# nrf9220_application register map
Vendor: Nordic Semiconductor; Series: nRF92; File version: 1
CPU: CM33 r0p4, little endian, MPU, FPU, 3 interrupt priority bits, 480 interrupts, 4 SAU regions
Registers are 32-bit, read-write, reset 0x0 unless marked. A register's access mark holds for its fields unless they carry their own. Offsets are from the block's base; [hi:lo] are bit positions; lines under a group give offsets from that group; {n}, {i} and the like mark numbered series.

## GLOBAL_MICR_NS — MICR
Base 0x0FFF6000
0x80 SIPINFO group — SIP-specific device info
  0x00 PARTNO ro reset 0xFFFFFFFF — SIP part number
  {0x4+j} HWREVISION[{j}] (j=0..3) 8-bit ro reset 0xFF — Description collection: SIP hardware revision, encoded in ASCII, ex B0A or B1A
    [7:0] HWREVISION
  {0x8+j} VARIANT[{j}] (j=0..3) 8-bit ro reset 0xFF — Description collection: SIP VARIANT, encoded in ASCII, ex SIAA, SIBA or SICA
    [7:0] VARIANT
  {0x10+j} TESTSITE[{j}] (j=0..3) 8-bit ro — Description collection: Test site, in ascii
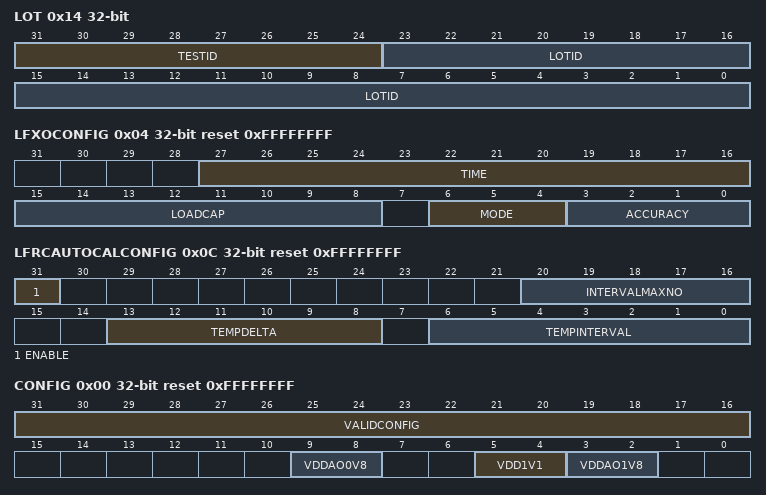
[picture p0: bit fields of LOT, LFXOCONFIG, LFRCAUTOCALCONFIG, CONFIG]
  0x14 LOT ro — Lot number + test index in hex format (number digits 0-9).
    [31:24] TESTID — Test ID in hex format
    [23:0] LOTID — Lot number in hex format
  {0x18+j} TESTPROGRAMID[{j}] (j=0..3) 8-bit ro — Description collection: Test program id, in ascii
  0x1C OSATPARTNO ro reset 0xFFFFFFFF — OSAT part number
  {0x20+j} HWBUILDVERSION[{j}] (j=0..3) 8-bit ro reset 0xFF — Description collection: OSAT production build version
  0x24 OVERRIDE group — Unspecified
    0x00 LFOSC group — Unspecified
      0x00 CONFIG reset 0xFFFFFFFF — LF oscillator configuration. Note. This configuration overrides corresponding LF oscillator configuration in BICR when set.
        [3:0] SRC — LF oscillator source.
          15=Unconfigured (LF oscillator source is unconfigured. Default will be used.); 0=LFXO (Use LFXO as source for the LF oscillator.); 1=LFRC (Use LFRC as source for the LF oscillator.); 2=LFLPRC (Use LFLPRC as source for the LF oscillator.); 3=Synth (Use LF Synth as source for the LF oscillator.)
      0x04 LFXOCONFIG reset 0xFFFFFFFF — LFXO configuration. Note. This configuration overrides corresponding LFXO configuration in BICR when set.
        [27:16] TIME — LFXO startup time in ms.
          0xFFF=Unconfigured (Startup time has not been configured.)
        [15:8] LOADCAP — Built-in load capacitors selection in 1 pF steps. Max. value 25 pF.
          255=Unconfigured (The built-in load capacitors is unconfigured. LFXO will not start unless LOADCAP is configured.); 0=External (Do not use the built-in load capacitors, only external capacitors will be used.)
        [6:4] MODE — LFXO mode. LFXO will not start unless MODE is configured.
          7=Unconfigured (The mode is unconfigured.); 0=Pierce (LFXO Pierce mode.); 1=PIXO (LFXO PIXO mode.); 2=ExtSine (LFXO in external sine wave mode.); 3=ExtSquare (LFXO in external square wave mode.)
        [3:0] ACCURACY — LFXO crystal or external signal accuracy.
          15=Unconfigured (The accuracy is unconfigured.); 0=500ppm (LFXO crystal or external signal has an accuracy of 500 ppm.); 1=250ppm (LFXO crystal or external signal has an accuracy of 250 ppm.); 2=150ppm (LFXO crystal or external signal has an accuracy of 150 ppm.); 3=100ppm (LFXO crystal or external signal has an accuracy of 100 ppm.); 4=75ppm (LFXO crystal or external signal has an accuracy of 75 ppm.); 5=50ppm (LFXO crystal or external signal has an accuracy of 50 ppm.); 6=30ppm (LFXO crystal or external signal has an accuracy of 30 ppm.); 7=20ppm (LFXO crystal or external signal has an accuracy of 20 ppm.)
      0x08 LFXOCAL reset 0xFFFFFFFF — LFXO calibration needed. Must be written to 0xFFFFFFFF after any modification of the LFXO board circuit, load capacitance, or crystal swap. Note. This configuration overrides corresponding LFXO calibration in BICR when set.
        [31:0] LFXOCAL — LFXO calibration needed. Must be written to 0xFFFFFFFF after any modification of the LFXO board circuit, load capacitance, or crystal swap.
          0xFFFFFFFF=Calibrate the LFXO at startup
      0x0C LFRCAUTOCALCONFIG reset 0xFFFFFFFF — LFRC autocalibration configuration. Note. This configuration overrides corresponding LFRC autocalibration configuration in BICR when set.
        [31] ENABLE — LFRC.AUTOCALCONFIG register enable.
          0=Enabled (LFRC.AUTOCALCONFIG register has been configured and can be used.); 1=Disabled (LFRC.AUTOCALCONFIG register has not been configured and cannot be used.)
        [20:16] INTERVALMAXNO — Maximum number of TEMPINTERVAL periods in between calibrations, independent of temperature changes.
        [13:8] TEMPDELTA — Temperature delta that should trigger a calibration in 0.25 degrees steps.
        [6:0] TEMPINTERVAL — Temperature measurement interval in 0.25 s steps.
    0x10 HFXO64M group — Unspecified
      0x00 CONFIG reset 0xFFFFFFFF — HFXO64M configuration. Note. This configuration overrides corresponding XO configuration in BICR when set.
        [2:0] MODE — HFXO64M mode.
          7=Unconfigured (The mode is unconfigured.); 0=Normal operating mode; 1=TCXO (TCXO/bypass mode); {v}=Crystal{v} (Reserved value) (v=2..6)
      0x04 STARTUPTIME reset 0xFFFFFFFF — HFXO64M startup time in us. Note. This configuration overrides corresponding XO configuration in BICR when set.
        [31:0] TIME — HFXO64M startup time in us.
          0xFFFFFFFF=Unconfigured (Startup time has not been configured.)
    0x18 POWER group — Unspecified
      0x00 CONFIG reset 0xFFFFFFFF — Power configuration of power rails. Note. This configuration overrides corresponding power configuration in BICR when set.
        [31:16] VALIDCONFIG — Indication of valid configuration for this register.
          0xFFFF=Invalid (This register is not programmed with valid content. Any other value than the value for valid.); 0xAC53=Valid (This register is programmed with valid content.)
        [9:8] VDDAO0V8 — VDD_AO_0V8 power configuration.
          3=Unconfigured (Power rail is unconfigured.); 0=Internal (Power rail is configured to use the internal regulator.); 1=External (Power rail is configured to be externally powered.)
        [5:4] VDD1V1 — VDD_1V1 power configuration.
          3=Unconfigured (Power rail is unconfigured.); 0=Internal (Power rail is configured to use the internal regulator. This option requires the presence of an inductor for the 1V1 DCDC regulator.); 1=External (Power rail is configured to be externally powered.)
        [3:2] VDDAO1V8 — VDD_AO_1V8 power configuration.
          3=Unconfigured (Power rail is unconfigured.); 0=Internal (Power rail is configured to use the internal regulator. This option requires the presence of an inductor for the 1V8 DCDC regulator.); 1=External (Power rail is configured to be externally powered.)
